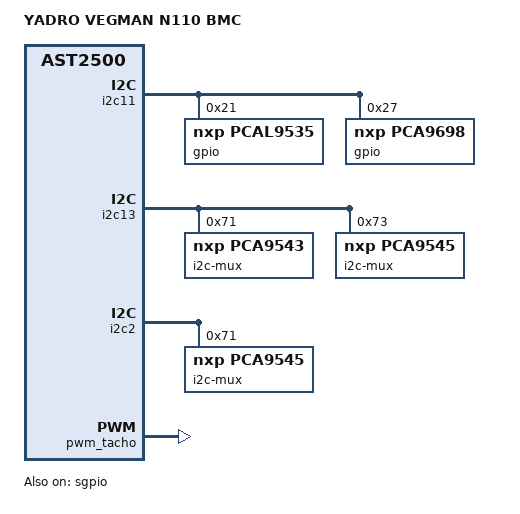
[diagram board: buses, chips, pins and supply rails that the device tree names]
/dts-v1/;
#include "aspeed-bmc-vegman.dtsi"
/ {
	model = "YADRO VEGMAN N110 BMC";
	compatible = "yadro,vegman-n110-bmc", "aspeed,ast2500";
};
&gpio {
	status = "okay";
	gpio-line-names =
	 	"CHASSIS_INTRUSION","CASE_OPEN_FAULT_RST","","","SPEAKER_BMC","FM_FORCE_BMC_UPDATE","","",
	 	"","","","","","","","",
	 	"","","","","","","","",
	 	"","","","","","","","",
	 	"RESET_BUTTON","RESET_OUT","POWER_BUTTON","POWER_OUT","","","","",
	 	"NMI_OUT","PCIE_NIC_ALERT","","","SKT0_FAULT_LED","","RST_RGMII_PHYRST_DNP","",
	 	"CPU_ERR2","CPU_CATERR","PCH_BMC_THERMTRIP","","IRQ_NMI_EVENT","","","",
	 	"PWRGD_P3V3_RISER1","PWRGD_P3V3_RISER2","PWRGD_P3V3_RISER3","","MIO_BIOS_SEL","_SPI_FLASH_HOLD","_SPI_FLASH_WP","FM_240VA_STATUS",
	 	"","","","","","","","",
	 	"","","","","","","","",
	 	"","","","","","","","",
	 	"","","","","","","","",
	 	"","","","","","","","",
	 	"","","","","","","","",
	 	"","","","","","","","_SPI2_BMC_CS_SEL",
	 	"","","","","","","","",
	 	"","","","","","","","",
	 	"_SPI_RMM4_LITE_CS","","","","","","","",
	 	"_SPI2_BMC_CS1","","","IRQ_SML0_ALERT_MUX","FP_LED_STATUS_GREEN","FP_LED_STATUS_AMBER","FP_ID_LED","",
	 	"","","","","","","","",
	 	"","","","","","","","",
	 	"","","","","","","","",
	 	"","","","","","","","",
	 	"","","","","","","","",
	 	"SIO_S3","SIO_S5","","SIO_ONCONTROL","","","","",
	 	"FM_BMC_PWR_BTN","SIO_POWER_GOOD","FM_BMC_PWRBTN_OUT","FM_BMC_PCH_SCI_LPC","","","","",
	 	"","IRQ_SML1_PMBUS_ALERT","FM_PVCCIN_CPU0_PWR_IN_ALERT","FM_PVCCIN_CPU1_PWR_IN_ALERT","BMC_SYS_PWR_FAULT","BMC_SYS_PWR_OK","SMI","POST_COMPLETE",
	 	"FM_CPU_BMCINIT","NMI_BUTTON","ID_BUTTON","PS_PWROK","","","","",
	 	"","","","","","","","";
};
&sgpio {
	ngpios = <80>;
	bus-frequency = <2000000>;
	status = "okay";
	gpio-line-names =
	 	"CPU1_PRESENCE","","CPU1_THERMTRIP","","CPU1_VRHOT","","CPU1_FIVR_FAULT","","CPU1_MEM_ABCD_VRHOT","","CPU1_MEM_EFGH_VRHOT","","","","","",
	 	"CPU1_MISMATCH","","CPU1_MEM_THERM_EVENT","","CPU2_PRESENCE","","CPU2_THERMTRIP","","CPU2_VRHOT","","CPU2_FIVR_FAULT","","CPU2_MEM_ABCD_VRHOT","","CPU2_MEM_EFGH_VRHOT","",
	 	"","","","","CPU2_MISMATCH","","CPU2_MEM_THERM_EVENT","","","","","","","","","",
	 	"","","","","","","","","","","","","","","","",
	 	"","","","","","","","","","","","","","","","",
	 	"SGPIO_PLD_MINOR_REV_BIT0","","SGPIO_PLD_MINOR_REV_BIT1","","SGPIO_PLD_MINOR_REV_BIT2","","SGPIO_PLD_MINOR_REV_BIT3","","SGPIO_PLD_MAJOR_REV_BIT0","","SGPIO_PLD_MAJOR_REV_BIT1","","SGPIO_PLD_MAJOR_REV_BIT2","","SGPIO_PLD_MAJOR_REV_BIT3","",
	 	"MAIN_PLD_MINOR_REV_BIT0","","MAIN_PLD_MINOR_REV_BIT1","","MAIN_PLD_MINOR_REV_BIT2","","MAIN_PLD_MINOR_REV_BIT3","","MAIN_PLD_MAJOR_REV_BIT0","","MAIN_PLD_MAJOR_REV_BIT1","","MAIN_PLD_MAJOR_REV_BIT2","","MAIN_PLD_MAJOR_REV_BIT3","",
	 	"","","","","","","","","","","","","","","","",
	 	"","","","","","","","","","","","","","","","",
	 	"","","","","","","","","","","","","","","","";
};
&i2c11 {
	gpio@21 {
		compatible = "nxp,pcal9535";
		reg = <0x21>;
		gpio-controller;
		#gpio-cells = <2>;
		gpio-line-names =
		 	"", "", "", "", "", "", "PE_PCH_SCR_CLKREQ", "",
		 	"", "PE_PCH_MEZ_PRSNT", "PE_PCH_MEZ_PRSNT_", "NIC_4_PE_PRSNT", "NIC_3_PE_PRSNT", "NIC_2_PE_PRSNT", "NIC_1_PE_PRSNT", "";
	};
	gpio@27 {
		compatible = "nxp,pca9698";
		reg = <0x27>;
		gpio-controller;
		#gpio-cells = <2>;
		gpio-line-names =
		 	"PWRGD_PS_PWROK", "PWRGD_DSW_PWROK", "PWRGD_P5V_AUX", "PWRGD_P3V3_AUX", "PWRGD_P5V", "PWRGD_P3V3", "PWRGD_P1V8_PCH_AUX", "PWRGD_PCH_PVNN_AUX",
		 	"PWRGD_P1V05_PCH_AUX", "PWRGD_PCH_AUX_VRS", "PWRGD_PVCCIN_CPU0", "PWRGD_PVCCSA_CPU0", "PWRGD_PVCCIO_CPU0", "PWRGD_PVMCP_CPU0", "PWRGD_P1V0_CPU0", "PWRGD_PVDDQ_ABC_CPU0",
		 	"PWRGD_PVPP_ABC_CPU0", "PWRGD_PVTT_ABC_CPU0", "PWRGD_PVDDQ_DEF_CPU0", "PWRGD_PVPP_DEF_CPU0", "PWRGD_PVTT_DEF_CPU0", "", "", "",
		 	"", "", "", "", "", "", "", "",
		 	"", "", "", "", "", "", "", "";
	};
};
&i2c13 {
	i2c-mux@71 {
		compatible = "nxp,pca9543";
		reg = <0x71>;
		#address-cells = <1>;
		#size-cells = <0>;
		i2c-mux-idle-disconnect;
	};
	i2c-mux@73 {
		compatible = "nxp,pca9545";
		reg = <0x73>;
		#address-cells = <1>;
		#size-cells = <0>;
		i2c-mux-idle-disconnect;
	};
};
&i2c2 {
	i2c-mux@71 {
		compatible = "nxp,pca9545";
		reg = <0x71>;
		#address-cells = <1>;
		#size-cells = <0>;
		i2c-mux-idle-disconnect;
	};
};
&pwm_tacho {
	status = "okay";
	pinctrl-names = "default";
	pinctrl-0 = <&pinctrl_pwm0_default &pinctrl_pwm1_default
			 &pinctrl_pwm2_default &pinctrl_pwm3_default
			 &pinctrl_pwm4_default &pinctrl_pwm5_default>;
	fan@0 {
		reg = <0x00>;
		aspeed,fan-tach-ch = /bits/ 8 <0x00 0x06>;
	};
	fan@1 {
		reg = <0x01>;
		aspeed,fan-tach-ch = /bits/ 8 <0x01 0x08>;
	};
	fan@2 {
		reg = <0x02>;
		aspeed,fan-tach-ch = /bits/ 8 <0x02 0x09>;
	};
	fan@3 {
		reg = <0x03>;
		aspeed,fan-tach-ch = /bits/ 8 <0x03 0x0A>;
	};
	fan@4 {
		reg = <0x04>;
		aspeed,fan-tach-ch = /bits/ 8 <0x04 0x0B>;
	};
	fan@5 {
		reg = <0x05>;
		aspeed,fan-tach-ch = /bits/ 8 <0x05>;
	};
};
